VERSION "FDI Standard CAN Link - DETA10A subset"

NS_ :

BS_:

BU_: FDI_IMU

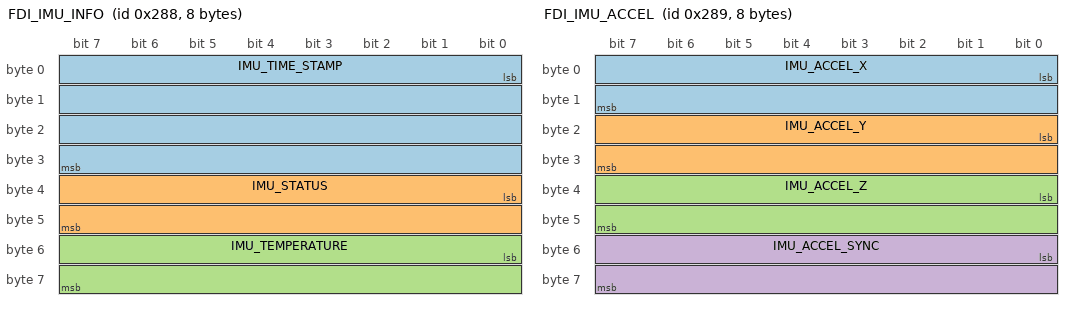
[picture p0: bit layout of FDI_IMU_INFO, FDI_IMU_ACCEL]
BO_ 648 FDI_IMU_INFO: 8 FDI_IMU
 SG_ IMU_TIME_STAMP : 0|32@1+ (0.01,0) [0|42949672.95] "us" Vector__XXX
 SG_ IMU_STATUS : 32|16@1+ (1,0) [0|65535] "" Vector__XXX
 SG_ IMU_TEMPERATURE : 48|16@1- (0.01,0) [-327.68|327.67] "C" Vector__XXX

BO_ 649 FDI_IMU_ACCEL: 8 FDI_IMU
 SG_ IMU_ACCEL_X : 0|16@1- (0.0010197162,0) [-33.41|33.41] "g" Vector__XXX
 SG_ IMU_ACCEL_Y : 16|16@1- (0.0010197162,0) [-33.41|33.41] "g" Vector__XXX
 SG_ IMU_ACCEL_Z : 32|16@1- (0.0010197162,0) [-33.41|33.41] "g" Vector__XXX
 SG_ IMU_ACCEL_SYNC : 48|16@1+ (1,0) [0|65535] "" Vector__XXX

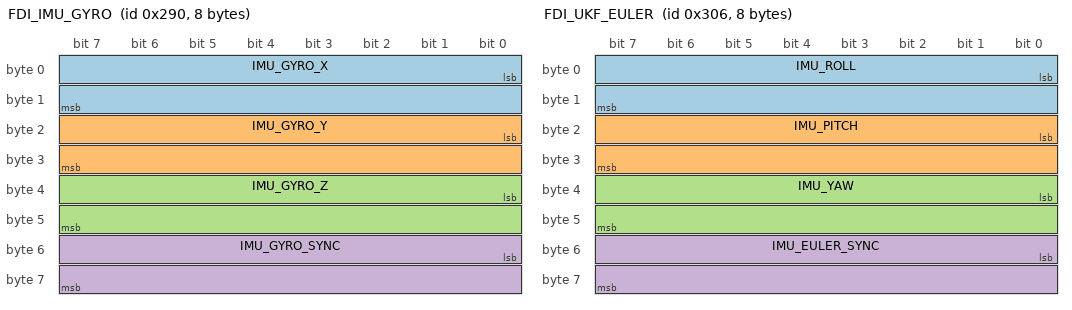
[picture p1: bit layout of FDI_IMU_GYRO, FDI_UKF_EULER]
BO_ 656 FDI_IMU_GYRO: 8 FDI_IMU
 SG_ IMU_GYRO_X : 0|16@1- (0.0572957795,0) [-1877.47|1877.47] "deg/s" Vector__XXX
 SG_ IMU_GYRO_Y : 16|16@1- (0.0572957795,0) [-1877.47|1877.47] "deg/s" Vector__XXX
 SG_ IMU_GYRO_Z : 32|16@1- (0.0572957795,0) [-1877.47|1877.47] "deg/s" Vector__XXX
 SG_ IMU_GYRO_SYNC : 48|16@1+ (1,0) [0|65535] "" Vector__XXX

BO_ 774 FDI_UKF_EULER: 8 FDI_IMU
 SG_ IMU_ROLL : 0|16@1- (0.0057295780,0) [-187.75|187.75] "deg" Vector__XXX
 SG_ IMU_PITCH : 16|16@1- (0.0057295780,0) [-187.75|187.75] "deg" Vector__XXX
 SG_ IMU_YAW : 32|16@1- (0.0057295780,0) [-187.75|187.75] "deg" Vector__XXX
 SG_ IMU_EULER_SYNC : 48|16@1+ (1,0) [0|65535] "" Vector__XXX

CM_ BU_ FDI_IMU "FDI Systems DETA10A 9-axis IMU/AHRS on the vehicle CAN bus (1 Mbps, 11-bit IDs 0x288-0x306; FDI doc ID numbers are HEX).";
CM_ BO_ 648 "FDI_ECAN_MSG_IMU_INFO: device timestamp, status word, sensor temperature.";
CM_ BO_ 649 "FDI_ECAN_MSG_IMU_ACCEL: native int16 at 0.01 m/s^2 per bit, rescaled to g (0.01/9.80665).";
CM_ BO_ 656 "FDI_ECAN_MSG_IMU_GYRO: native int16 at 0.001 rad/s per bit, rescaled to deg/s.";
CM_ BO_ 774 "FDI_ECAN_MSG_UKF_EULER: native int16 at 0.0001 rad per bit, rescaled to deg.";
CM_ "Byte order little-endian, verified against a bench candump 2026-07. Frames 0x289/0x290/0x306 are DLC 8 on the wire (docs claim 6): bytes 6-7 carry a sync/sequence counter, mapped as *_SYNC and excluded from the signal filter.";
